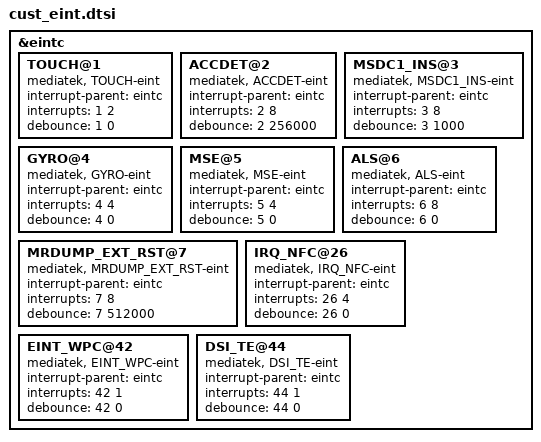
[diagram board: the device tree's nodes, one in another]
/*
 * Generated by MTK SP DrvGen Version 03.13.6 for MT6755. Copyright MediaTek Inc. (C) 2013.
 * Mon Aug 12 22:58:53 2019
 * Do Not Modify the File.
 */

/*************************
 * EINT DTSI File
*************************/

&eintc {
	TOUCH@1 {
		compatible = "mediatek, TOUCH-eint";
		interrupt-parent = <&eintc>;
		interrupts = <1 2>;
		debounce = <1 0>;
	};

	ACCDET@2 {
		compatible = "mediatek, ACCDET-eint";
		interrupt-parent = <&eintc>;
		interrupts = <2 8>;
		debounce = <2 256000>;
	};

	MSDC1_INS@3 {
		compatible = "mediatek, MSDC1_INS-eint";
		interrupt-parent = <&eintc>;
		interrupts = <3 8>;
		debounce = <3 1000>;
	};

	GYRO@4 {
		compatible = "mediatek, GYRO-eint";
		interrupt-parent = <&eintc>;
		interrupts = <4 4>;
		debounce = <4 0>;
	};

	MSE@5 {
		compatible = "mediatek, MSE-eint";
		interrupt-parent = <&eintc>;
		interrupts = <5 4>;
		debounce = <5 0>;
	};

	ALS@6 {
		compatible = "mediatek, ALS-eint";
		interrupt-parent = <&eintc>;
		interrupts = <6 8>;
		debounce = <6 0>;
	};

	MRDUMP_EXT_RST@7 {
		compatible = "mediatek, MRDUMP_EXT_RST-eint";
		interrupt-parent = <&eintc>;
		interrupts = <7 8>;
		debounce = <7 512000>;
	};

	IRQ_NFC@26 {
		compatible = "mediatek, IRQ_NFC-eint";
		interrupt-parent = <&eintc>;
		interrupts = <26 4>;
		debounce = <26 0>;
	};

	EINT_WPC@42 {
		compatible = "mediatek, EINT_WPC-eint";
		interrupt-parent = <&eintc>;
		interrupts = <42 1>;
		debounce = <42 0>;
	};

	DSI_TE@44 {
		compatible = "mediatek, DSI_TE-eint";
		interrupt-parent = <&eintc>;
		interrupts = <44 1>;
		debounce = <44 0>;
	};

};
